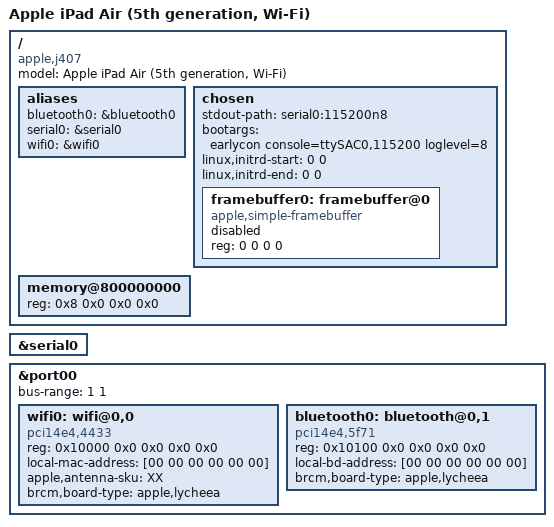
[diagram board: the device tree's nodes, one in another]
// SPDX-License-Identifier: GPL-2.0+ OR MIT
/*
 * Apple iPad Air (5th generation, Wi-Fi)
 *
 * ProductType: iPad13,16
 * target-type: J407
 * SoC: T8103 / M1
 *
 * This is intentionally minimal. T8103 SoC topology belongs in upstream
 * t8103.dtsi. Add J407-specific peripherals only after cross-checking them
 * against the public J407 Apple Device Tree and/or live hardware.
 */

/dts-v1/;

#include "t8103.dtsi"

/ {
	compatible = "apple,j407", "apple,t8103", "apple,arm-platform";
	model = "Apple iPad Air (5th generation, Wi-Fi)";
	#address-cells = <2>;
	#size-cells = <2>;

	aliases {
		bluetooth0 = &bluetooth0;
		serial0 = &serial0;
		wifi0 = &wifi0;
	};

	chosen {
		#address-cells = <2>;
		#size-cells = <2>;
		ranges;
		stdout-path = "serial0:115200n8";

		/*
		 * Mainline's Apple S5L earlycon driver can derive the UART from
		 * stdout-path. Keep the first bring-up noisy and independent of a
		 * root filesystem; a later loader may replace bootargs in its DTB.
		 */
		bootargs = "earlycon console=ttySAC0,115200 loglevel=8";

		/* Fixed-size placeholders patched by the entry loader when used. */
		linux,initrd-start = <0 0>;
		linux,initrd-end = <0 0>;

		/*
		 * m1n1 kboot looks up /chosen/framebuffer, patches this node from
		 * Apple's live video boot arguments and removes status when a usable
		 * firmware framebuffer exists. Keeping it disabled is safe when no
		 * framebuffer survives the handoff.
		 */
		framebuffer0: framebuffer@0 {
			compatible = "apple,simple-framebuffer", "simple-framebuffer";
			reg = <0 0 0 0>;
			status = "disabled";
		};
	};

	/*
	 * T8103 DRAM starts at 0x8_00000000. The usable size is runtime data
	 * and must account for firmware carveouts, so keep the reg size zero
	 * until linux_fdt_patch_runtime() receives the entry contract.
	 */
	memory@800000000 {
		device_type = "memory";
		reg = <0x8 0x0 0x0 0x0>;
	};
};

/*
 * J407's public ADT marks uart0 as the boot console and its translated
 * address/IRQ match mainline t8103.dtsi (0x235200000 / AIC IRQ 605).
 */
&serial0 {
	status = "okay";
};

/*
 * J407's built-in radio lives behind pci-bridge0, which corresponds to
 * T8103 port00. The public ADT identifies WLAN as BCM4387C2 and PCI function
 * 0; Bluetooth is the sibling PCI function 1 of the same BCM4387 module.
 *
 * J407 bridge0's PERST# GPIO is 152, matching t8103.dtsi's port00 reset-gpio.
 * The ADT module-instance decodes to "lycheea", which is the Apple radio
 * module codename Linux uses for firmware/NVRAM filename selection.
 *
 * m1n1 kboot fills the per-device values through the wifi0/bluetooth0 aliases:
 * WLAN/BT addresses, antenna SKU, WLAN calibration and Bluetooth Taurus data.
 */
&port00 {
	bus-range = <1 1>;

	wifi0: wifi@0,0 {
		compatible = "pci14e4,4433"; /* BCM4387 Wi-Fi */
		reg = <0x10000 0x0 0x0 0x0 0x0>;

		/* Filled/overridden from the live Apple Device Tree by m1n1. */
		local-mac-address = [00 00 00 00 00 00];
		apple,antenna-sku = "XX";
		brcm,board-type = "apple,lycheea";
	};

	bluetooth0: bluetooth@0,1 {
		compatible = "pci14e4,5f71"; /* BCM4387 Bluetooth */
		reg = <0x10100 0x0 0x0 0x0 0x0>;

		/* Filled/overridden from the live Apple Device Tree by m1n1. */
		local-bd-address = [00 00 00 00 00 00];
		brcm,board-type = "apple,lycheea";
	};
};

/*
 * CPU release state, usable-memory ranges and firmware-derived values are
 * intentionally patched/supplied from the live boot environment/ADT.
 */
